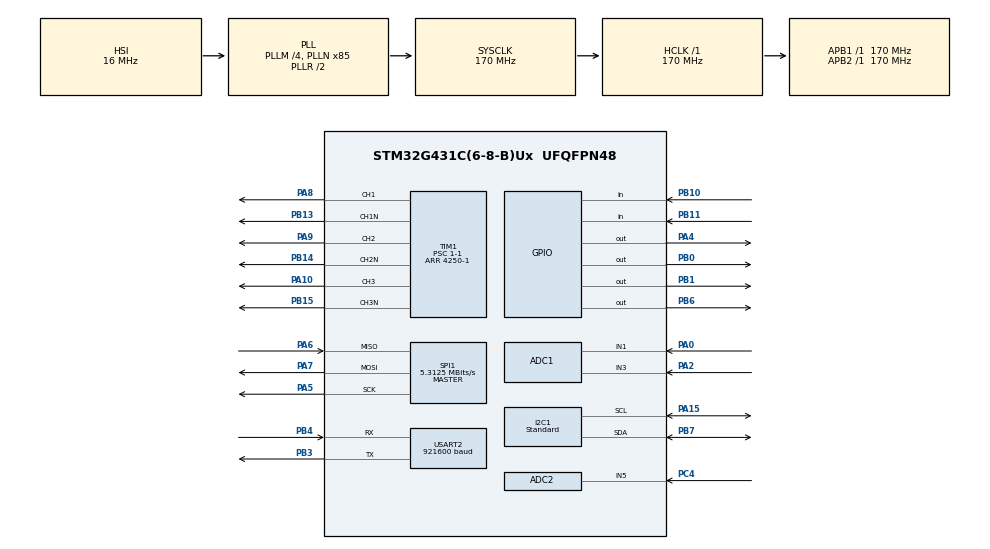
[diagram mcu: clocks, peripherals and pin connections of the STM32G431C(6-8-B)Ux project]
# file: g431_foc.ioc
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ADC1.ContinuousConvMode=DISABLE
ADC1.DMAContinuousRequests=DISABLE
ADC1.EnableInjectedConversion=ENABLE
ADC1.EnableRegularConversion=DISABLE
ADC1.ExternalTrigInjecConv=ADC_EXTERNALTRIGINJEC_T1_CC4
ADC1.InjNumberOfConversion=2
ADC1.InjectedChannel-1\#ChannelInjectedConversion=ADC_CHANNEL_1
ADC1.InjectedChannel-2\#ChannelInjectedConversion=ADC_CHANNEL_3
ADC1.InjectedOffsetNumber-1\#ChannelInjectedConversion=ADC_OFFSET_NONE
ADC1.InjectedOffsetNumber-2\#ChannelInjectedConversion=ADC_OFFSET_NONE
ADC1.InjectedRank-1\#ChannelInjectedConversion=1
ADC1.InjectedRank-2\#ChannelInjectedConversion=2
ADC1.InjectedSamplingTime-1\#ChannelInjectedConversion=ADC_SAMPLETIME_6CYCLES_5
ADC1.InjectedSamplingTime-2\#ChannelInjectedConversion=ADC_SAMPLETIME_6CYCLES_5
ADC1.Rank1_Channel=ADC_CHANNEL_1
ADC1.Rank2_Channel=ADC_CHANNEL_3
ADC1.master=1
ADC2.Channel-0\#ChannelRegularConversion=ADC_CHANNEL_5
ADC2.ContinuousConvMode=ENABLE
ADC2.DMAContinuousRequests=ENABLE
ADC2.NbrOfConversion=1
ADC2.NbrOfConversionFlag=1
ADC2.OffsetNumber-0\#ChannelRegularConversion=ADC_OFFSET_NONE
ADC2.Rank-0\#ChannelRegularConversion=1
ADC2.SamplingTime-0\#ChannelRegularConversion=ADC_SAMPLETIME_12CYCLES_5
Dma.ADC2.0.Direction=DMA_PERIPH_TO_MEMORY
Dma.ADC2.0.EventEnable=DISABLE
Dma.ADC2.0.Instance=DMA1_Channel2
Dma.ADC2.0.MemDataAlignment=DMA_MDATAALIGN_HALFWORD
Dma.ADC2.0.MemInc=DMA_MINC_ENABLE
Dma.ADC2.0.Mode=DMA_CIRCULAR
Dma.ADC2.0.PeriphDataAlignment=DMA_PDATAALIGN_HALFWORD
Dma.ADC2.0.PeriphInc=DMA_PINC_DISABLE
Dma.ADC2.0.Polarity=HAL_DMAMUX_REQ_GEN_RISING
Dma.ADC2.0.Priority=DMA_PRIORITY_LOW
Dma.ADC2.0.RequestNumber=1
Dma.ADC2.0.SignalID=NONE
Dma.ADC2.0.SyncEnable=DISABLE
Dma.ADC2.0.SyncPolarity=HAL_DMAMUX_SYNC_NO_EVENT
Dma.ADC2.0.SyncRequestNumber=1
Dma.ADC2.0.SyncSignalID=NONE
Dma.I2C1_RX.1.Direction=DMA_PERIPH_TO_MEMORY
Dma.I2C1_RX.1.EventEnable=DISABLE
Dma.I2C1_RX.1.Instance=DMA1_Channel1
Dma.I2C1_RX.1.MemDataAlignment=DMA_MDATAALIGN_BYTE
Dma.I2C1_RX.1.MemInc=DMA_MINC_ENABLE
Dma.I2C1_RX.1.Mode=DMA_NORMAL
Dma.I2C1_RX.1.PeriphDataAlignment=DMA_PDATAALIGN_BYTE
Dma.I2C1_RX.1.PeriphInc=DMA_PINC_DISABLE
Dma.I2C1_RX.1.Polarity=HAL_DMAMUX_REQ_GEN_RISING
Dma.I2C1_RX.1.Priority=DMA_PRIORITY_LOW
Dma.I2C1_RX.1.RequestNumber=1
Dma.I2C1_RX.1.SignalID=NONE
Dma.I2C1_RX.1.SyncEnable=DISABLE
Dma.I2C1_RX.1.SyncPolarity=HAL_DMAMUX_SYNC_NO_EVENT
Dma.I2C1_RX.1.SyncRequestNumber=1
Dma.I2C1_RX.1.SyncSignalID=NONE
Dma.I2C1_TX.2.Direction=DMA_MEMORY_TO_PERIPH
Dma.I2C1_TX.2.EventEnable=DISABLE
Dma.I2C1_TX.2.Instance=DMA1_Channel3
Dma.I2C1_TX.2.MemDataAlignment=DMA_MDATAALIGN_BYTE
Dma.I2C1_TX.2.MemInc=DMA_MINC_ENABLE
Dma.I2C1_TX.2.Mode=DMA_NORMAL
Dma.I2C1_TX.2.PeriphDataAlignment=DMA_PDATAALIGN_BYTE
Dma.I2C1_TX.2.PeriphInc=DMA_PINC_DISABLE
Dma.I2C1_TX.2.Polarity=HAL_DMAMUX_REQ_GEN_RISING
Dma.I2C1_TX.2.Priority=DMA_PRIORITY_LOW
Dma.I2C1_TX.2.RequestNumber=1
Dma.I2C1_TX.2.SignalID=NONE
Dma.I2C1_TX.2.SyncEnable=DISABLE
Dma.I2C1_TX.2.SyncPolarity=HAL_DMAMUX_SYNC_NO_EVENT
Dma.I2C1_TX.2.SyncRequestNumber=1
Dma.I2C1_TX.2.SyncSignalID=NONE
Dma.Request0=ADC2
Dma.Request1=I2C1_RX
Dma.Request2=I2C1_TX
Dma.Request3=USART2_RX
Dma.Request4=USART2_TX
Dma.Request5=SPI1_RX
Dma.Request6=SPI1_TX
Dma.SPI1_RX.5.Direction=DMA_PERIPH_TO_MEMORY
Dma.SPI1_RX.5.EventEnable=DISABLE
Dma.SPI1_RX.5.Instance=DMA1_Channel6
Dma.SPI1_RX.5.MemDataAlignment=DMA_MDATAALIGN_BYTE
Dma.SPI1_RX.5.MemInc=DMA_MINC_ENABLE
Dma.SPI1_RX.5.Mode=DMA_NORMAL
Dma.SPI1_RX.5.PeriphDataAlignment=DMA_PDATAALIGN_BYTE
Dma.SPI1_RX.5.PeriphInc=DMA_PINC_DISABLE
Dma.SPI1_RX.5.Polarity=HAL_DMAMUX_REQ_GEN_RISING
Dma.SPI1_RX.5.Priority=DMA_PRIORITY_LOW
Dma.SPI1_RX.5.RequestNumber=1
Dma.SPI1_RX.5.SignalID=NONE
Dma.SPI1_RX.5.SyncEnable=DISABLE
Dma.SPI1_RX.5.SyncPolarity=HAL_DMAMUX_SYNC_NO_EVENT
Dma.SPI1_RX.5.SyncRequestNumber=1
Dma.SPI1_RX.5.SyncSignalID=NONE
Dma.SPI1_TX.6.Direction=DMA_MEMORY_TO_PERIPH
Dma.SPI1_TX.6.EventEnable=DISABLE
Dma.SPI1_TX.6.Instance=DMA2_Channel1
Dma.SPI1_TX.6.MemDataAlignment=DMA_MDATAALIGN_BYTE
Dma.SPI1_TX.6.MemInc=DMA_MINC_ENABLE
Dma.SPI1_TX.6.Mode=DMA_NORMAL
Dma.SPI1_TX.6.PeriphDataAlignment=DMA_PDATAALIGN_BYTE
Dma.SPI1_TX.6.PeriphInc=DMA_PINC_DISABLE
Dma.SPI1_TX.6.Polarity=HAL_DMAMUX_REQ_GEN_RISING
Dma.SPI1_TX.6.Priority=DMA_PRIORITY_LOW
Dma.SPI1_TX.6.RequestNumber=1
Dma.SPI1_TX.6.SignalID=NONE
Dma.SPI1_TX.6.SyncEnable=DISABLE
Dma.SPI1_TX.6.SyncPolarity=HAL_DMAMUX_SYNC_NO_EVENT
Dma.SPI1_TX.6.SyncRequestNumber=1
Dma.SPI1_TX.6.SyncSignalID=NONE
Dma.USART2_RX.3.Direction=DMA_PERIPH_TO_MEMORY
Dma.USART2_RX.3.EventEnable=DISABLE
Dma.USART2_RX.3.Instance=DMA1_Channel4
Dma.USART2_RX.3.MemDataAlignment=DMA_MDATAALIGN_BYTE
Dma.USART2_RX.3.MemInc=DMA_MINC_ENABLE
Dma.USART2_RX.3.Mode=DMA_NORMAL
Dma.USART2_RX.3.PeriphDataAlignment=DMA_PDATAALIGN_BYTE
Dma.USART2_RX.3.PeriphInc=DMA_PINC_DISABLE
Dma.USART2_RX.3.Polarity=HAL_DMAMUX_REQ_GEN_RISING
Dma.USART2_RX.3.Priority=DMA_PRIORITY_LOW
Dma.USART2_RX.3.RequestNumber=1
Dma.USART2_RX.3.SignalID=NONE
Dma.USART2_RX.3.SyncEnable=DISABLE
Dma.USART2_RX.3.SyncPolarity=HAL_DMAMUX_SYNC_NO_EVENT
Dma.USART2_RX.3.SyncRequestNumber=1
Dma.USART2_RX.3.SyncSignalID=NONE
Dma.USART2_TX.4.Direction=DMA_MEMORY_TO_PERIPH
Dma.USART2_TX.4.EventEnable=DISABLE
Dma.USART2_TX.4.Instance=DMA1_Channel5
Dma.USART2_TX.4.MemDataAlignment=DMA_MDATAALIGN_BYTE
Dma.USART2_TX.4.MemInc=DMA_MINC_ENABLE
Dma.USART2_TX.4.Mode=DMA_NORMAL
Dma.USART2_TX.4.PeriphDataAlignment=DMA_PDATAALIGN_BYTE
Dma.USART2_TX.4.PeriphInc=DMA_PINC_DISABLE
Dma.USART2_TX.4.Polarity=HAL_DMAMUX_REQ_GEN_RISING
Dma.USART2_TX.4.Priority=DMA_PRIORITY_LOW
Dma.USART2_TX.4.RequestNumber=1
Dma.USART2_TX.4.SignalID=NONE
Dma.USART2_TX.4.SyncEnable=DISABLE
Dma.USART2_TX.4.SyncPolarity=HAL_DMAMUX_SYNC_NO_EVENT
Dma.USART2_TX.4.SyncRequestNumber=1
Dma.USART2_TX.4.SyncSignalID=NONE
I2C1.I2C_Speed_Mode=I2C_Standard
I2C1.Timing=0x40B285C2
Mcu.Family=STM32G4
Mcu.Name=STM32G431C(6-8-B)Ux
Mcu.Package=UFQFPN48
NVIC.ADC1_2_IRQn=true\:0\:0\:false\:false\:true\:true\:true\:true
NVIC.DMA1_Channel1_IRQn=true\:3\:0\:true\:false\:true\:false\:true\:true
NVIC.DMA1_Channel2_IRQn=true\:0\:0\:false\:false\:true\:false\:true\:true
NVIC.DMA1_Channel3_IRQn=true\:3\:0\:true\:false\:true\:false\:true\:true
NVIC.DMA1_Channel4_IRQn=true\:0\:0\:false\:false\:true\:false\:true\:true
NVIC.DMA1_Channel5_IRQn=true\:0\:0\:false\:false\:true\:false\:true\:true
NVIC.DMA1_Channel6_IRQn=true\:1\:0\:false\:false\:true\:false\:true\:true
NVIC.DMA2_Channel1_IRQn=true\:1\:0\:false\:false\:true\:false\:true\:true
NVIC.I2C1_ER_IRQn=true\:3\:0\:true\:false\:true\:true\:true\:true
NVIC.I2C1_EV_IRQn=true\:3\:0\:true\:false\:true\:true\:true\:true
NVIC.PriorityGroup=NVIC_PRIORITYGROUP_4
NVIC.TIM2_IRQn=true\:2\:0\:true\:false\:true\:true\:true\:true
NVIC.USART2_IRQn=true\:3\:0\:true\:false\:true\:true\:true\:true
PA0.Mode=IN1-Single-Ended
PA0.Signal=ADC1_IN1
PA1.Signal=ADC1_IN2
PA10.Signal=S_TIM1_CH3
PA13.Mode=Serial_Wire
PA13.Signal=SYS_JTMS-SWDIO
PA14.Mode=Serial_Wire
PA14.Signal=SYS_JTCK-SWCLK
PA15.Mode=I2C
PA15.Signal=I2C1_SCL
PA2.Mode=IN3-Single-Ended
PA2.Signal=ADC1_IN3
PA4.Signal=GPIO_Output
PA5.Mode=Full_Duplex_Master
PA5.Signal=SPI1_SCK
PA6.Mode=Full_Duplex_Master
PA6.GPIO_PuPd=GPIO_PULLUP
PA6.Signal=SPI1_MISO
PA7.Mode=Full_Duplex_Master
PA7.Signal=SPI1_MOSI
PA8.Signal=S_TIM1_CH1
PA9.Signal=S_TIM1_CH2
PB0.GPIO_ModeDefaultOutputPP=GPIO_MODE_OUTPUT_OD
PB0.GPIO_PuPd=GPIO_PULLUP
PB0.Signal=GPIO_Output
PB1.GPIO_ModeDefaultOutputPP=GPIO_MODE_OUTPUT_OD
PB1.GPIO_PuPd=GPIO_PULLUP
PB1.Signal=GPIO_Output
PB10.GPIO_PuPd=GPIO_PULLUP
PB10.Signal=GPIO_Input
PB11.GPIO_PuPd=GPIO_PULLUP
PB11.Signal=GPIO_Input
PB13.Mode=PWM Generation1 CH1 CH1N
PB13.Signal=TIM1_CH1N
PB14.Mode=PWM Generation2 CH2 CH2N
PB14.Signal=TIM1_CH2N
PB15.Mode=PWM Generation3 CH3 CH3N
PB15.Signal=TIM1_CH3N
PB2.Signal=ADC2_IN12
PB3.Mode=Asynchronous
PB3.Signal=USART2_TX
PB4.Mode=Asynchronous
PB4.Signal=USART2_RX
PB6.Signal=GPIO_Output
PB7.Mode=I2C
PB7.Signal=I2C1_SDA
PC14-OSC32_IN.Mode=LSE-External-Oscillator
PC14-OSC32_IN.Signal=RCC_OSC32_IN
PC15-OSC32_OUT.Mode=LSE-External-Oscillator
PC15-OSC32_OUT.Signal=RCC_OSC32_OUT
PC4.Mode=IN5-Single-Ended
PC4.Signal=ADC2_IN5
PF0-OSC_IN.Mode=HSE-External-Oscillator
PF0-OSC_IN.Signal=RCC_OSC_IN
PF1-OSC_OUT.Mode=HSE-External-Oscillator
PF1-OSC_OUT.Signal=RCC_OSC_OUT
ProjectManager.HeapSize=0x200
ProjectManager.StackSize=0x400
ProjectManager.TargetToolchain=CMake
RCC.ADC12Freq_Value=170000000
RCC.AHBFreq_Value=170000000
RCC.APB1Freq_Value=170000000
RCC.APB1TimFreq_Value=170000000
RCC.APB2Freq_Value=170000000
RCC.APB2TimFreq_Value=170000000
RCC.CortexFreq_Value=170000000
RCC.EXTERNAL_CLOCK_VALUE=12288000
RCC.HCLKFreq_Value=170000000
RCC.HSE_VALUE=8000000
RCC.HSI48_VALUE=48000000
RCC.HSI_VALUE=16000000
RCC.PLLM=RCC_PLLM_DIV4
RCC.PLLN=85
RCC.SYSCLKFreq_VALUE=170000000
RCC.SYSCLKSource=RCC_SYSCLKSOURCE_PLLCLK
RCC.USBFreq_Value=170000000
RCC.VCOOutputFreq_Value=340000000
SH.S_TIM1_CH1.0=TIM1_CH1,PWM Generation1 CH1 CH1N
SH.S_TIM1_CH2.0=TIM1_CH2,PWM Generation2 CH2 CH2N
SH.S_TIM1_CH3.0=TIM1_CH3,PWM Generation3 CH3 CH3N
SPI1.BaudRatePrescaler=SPI_BAUDRATEPRESCALER_32
SPI1.CalculateBaudRate=5.3125 MBits/s
SPI1.CLKPhase=SPI_PHASE_2EDGE
SPI1.CLKPolarity=SPI_POLARITY_HIGH
SPI1.DataSize=SPI_DATASIZE_8BIT
SPI1.Direction=SPI_DIRECTION_2LINES
SPI1.Mode=SPI_MODE_MASTER
SPI1.NSSPMode=SPI_NSS_PULSE_DISABLE
SPI1.VirtualType=VM_MASTER
TIM1.Channel-PWM\ Generation1\ CH1\ CH1N=TIM_CHANNEL_1
TIM1.Channel-PWM\ Generation2\ CH2\ CH2N=TIM_CHANNEL_2
TIM1.Channel-PWM\ Generation3\ CH3\ CH3N=TIM_CHANNEL_3
TIM1.Channel-PWM\ Generation4\ No\ Output=TIM_CHANNEL_4
TIM1.CounterMode=TIM_COUNTERMODE_CENTERALIGNED1
TIM1.DeadTime=25
TIM1.OCMode_PWM-PWM\ Generation4\ No\ Output=TIM_OCMODE_PWM2
TIM1.PeriodNoDither=4250-1
TIM1.Prescaler=1-1
TIM1.PulseNoDither_4=5
TIM1.RepetitionCounter=1
TIM1.TIM_MasterOutputTrigger=TIM_TRGO_OC4REF
TIM2.PeriodNoDither=999
TIM2.Prescaler=169
USART2.BaudRate=921600
USART2.VirtualMode-Asynchronous=VM_ASYNC
VP_SYS_VS_DBSignals.Mode=DisableDeadBatterySignals
VP_TIM1_VS_ClockSourceINT.Mode=Internal
VP_TIM1_VS_no_output4.Mode=PWM Generation4 No Output
VP_TIM2_VS_ClockSourceINT.Mode=Internal
board=custom

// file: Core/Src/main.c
/* USER CODE BEGIN Header */
/**
  ******************************************************************************
  * @file           : main.c
  * @brief          : Main program body
  ******************************************************************************
  * @attention
  *
  * Copyright (c) 2026 STMicroelectronics.
  * All rights reserved.
  *
  * This software is licensed under terms that can be found in the LICENSE file
  * in the root directory of this software component.
  * If no LICENSE file comes with this software, it is provided AS-IS.
  *
  ******************************************************************************
  */
/* USER CODE END Header */
#include "main.h"
#include "adc.h"
#include "dma.h"
#include "i2c.h"
#include "spi.h"
#include "tim.h"
#include "usart.h"
#include "gpio.h"

/* USER CODE BEGIN Includes */
#include "pc_protocol.h"
#include "hardware_init.h"
#include "motor_system.h"
#include "motor_encoder_calibration.h"
#include "motor_parameters.h"
/* USER CODE END Includes */

void SystemClock_Config(void);

int main(void)
{

  /* MCU Configuration--------------------------------------------------------*/

  /* Reset of all peripherals, Initializes the Flash interface and the Systick. */
  HAL_Init();

  /* Configure the system clock */
  SystemClock_Config();

  /* Initialize all configured peripherals */
  // 配置板级引脚模式和初始电平。
  MX_GPIO_Init();
  // 配置 DMA 通道和中断，供后续采样与通信使用。
  MX_DMA_Init();
  // 配置 ADC1 的 U/W 相电流注入采样。
  MX_ADC1_Init();
  // 配置三相 PWM 定时器及 ADC 采样触发通道。
  MX_TIM1_Init();
  // 配置 1 ms 控制调度定时器。
  MX_TIM2_Init();
  // 配置 ADC2 的电位器常规采样和 DMA 请求。
  MX_ADC2_Init();
  // 配置 I2C1 外设。
  MX_I2C1_Init();
  // 配置上位机通信串口。
  MX_USART2_UART_Init();
  // 配置 MT6826S 编码器使用的 SPI 总线。
  MX_SPI1_Init();
  /* USER CODE BEGIN 2 */
  // 按板级时序校准采样、初始化控制模块并启动中断与通信。
  hardware_init();

  /* USER CODE END 2 */

  /* Infinite loop */
  while (1)
  {

    /* USER CODE BEGIN 3 */
    // 在前台处理参数辨识请求及结果保存，避免在控制中断中擦写 Flash。
    motor_parameters_background_task();
    // 处理上位机命令、应答和遥测发送。
    pc_protocol_task();
    // 推进编码器自校准，在前台处理设备寄存器事务。
    motor_encoder_cal_background_task();
  }
  /* USER CODE END 3 */
}

void SystemClock_Config(void)
{
  RCC_OscInitTypeDef RCC_OscInitStruct = {0};
  RCC_ClkInitTypeDef RCC_ClkInitStruct = {0};

  /** Configure the main internal regulator output voltage
  */
  HAL_PWREx_ControlVoltageScaling(PWR_REGULATOR_VOLTAGE_SCALE1_BOOST);

  /** Initializes the RCC Oscillators according to the specified parameters
  * in the RCC_OscInitTypeDef structure.
  */
  RCC_OscInitStruct.OscillatorType = RCC_OSCILLATORTYPE_HSI;
  RCC_OscInitStruct.HSIState = RCC_HSI_ON;
  RCC_OscInitStruct.HSICalibrationValue = RCC_HSICALIBRATION_DEFAULT;
  RCC_OscInitStruct.PLL.PLLState = RCC_PLL_ON;
  RCC_OscInitStruct.PLL.PLLSource = RCC_PLLSOURCE_HSI;
  RCC_OscInitStruct.PLL.PLLM = RCC_PLLM_DIV4;
  RCC_OscInitStruct.PLL.PLLN = 85;
  RCC_OscInitStruct.PLL.PLLP = RCC_PLLP_DIV2;
  RCC_OscInitStruct.PLL.PLLQ = RCC_PLLQ_DIV2;
  RCC_OscInitStruct.PLL.PLLR = RCC_PLLR_DIV2;
  if (HAL_RCC_OscConfig(&RCC_OscInitStruct) != HAL_OK)
  {
    Error_Handler();
  }

  /** Initializes the CPU, AHB and APB buses clocks
  */
  RCC_ClkInitStruct.ClockType = RCC_CLOCKTYPE_HCLK|RCC_CLOCKTYPE_SYSCLK
                              |RCC_CLOCKTYPE_PCLK1|RCC_CLOCKTYPE_PCLK2;
  RCC_ClkInitStruct.SYSCLKSource = RCC_SYSCLKSOURCE_PLLCLK;
  RCC_ClkInitStruct.AHBCLKDivider = RCC_SYSCLK_DIV1;
  RCC_ClkInitStruct.APB1CLKDivider = RCC_HCLK_DIV1;
  RCC_ClkInitStruct.APB2CLKDivider = RCC_HCLK_DIV1;

  if (HAL_RCC_ClockConfig(&RCC_ClkInitStruct, FLASH_LATENCY_4) != HAL_OK)
  {
    Error_Handler();
  }
}

void Error_Handler(void)
{
  __disable_irq();
  while (1)
  {
  }
}
